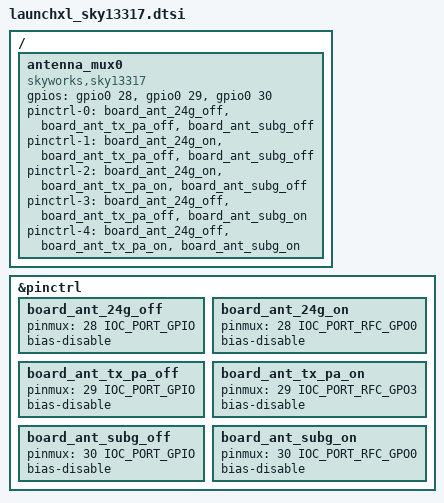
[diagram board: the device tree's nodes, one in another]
/*
 * Copyright (c) 2021 Florin Stancu
 *
 * SPDX-License-Identifier: Apache-2.0
 */

/ {
	/**
	 * The CC1352P LAUNCHXL has an on-board antenna switch (SKY13317-373LF) used to select the
	 * appropriate RF signal port based on the currently-used PHY.
	 *
	 * Truth table:
	 *
	 * Path        DIO28 DIO29 DIO30
	 * =========== ===== ===== =====
	 * Off         0     0     0
	 * Sub-1 GHz   0     0     1     // DIO30 mux to IOC_PORT_RFC_GPO0 for auto
	 * 2.4 GHz     1     0     0     // DIO28 mux to IOC_PORT_RFC_GPO0 for auto
	 * 20 dBm TX   0     1     0     // DIO29 mux to IOC_PORT_RFC_GPO3 for auto
	 */
	antenna_mux0: antenna_mux0 {
		compatible = "skyworks,sky13317";
		status = "okay";
		gpios = <&gpio0 28 GPIO_ACTIVE_HIGH>, <&gpio0 29 GPIO_ACTIVE_HIGH>,
			<&gpio0 30 GPIO_ACTIVE_HIGH>;
		pinctrl-0 = <&board_ant_24g_off &board_ant_tx_pa_off &board_ant_subg_off>;
		pinctrl-1 = <&board_ant_24g_on &board_ant_tx_pa_off &board_ant_subg_off>;
		pinctrl-2 = <&board_ant_24g_on &board_ant_tx_pa_on &board_ant_subg_off>;
		pinctrl-3 = <&board_ant_24g_off &board_ant_tx_pa_off &board_ant_subg_on>;
		pinctrl-4 = <&board_ant_24g_off &board_ant_tx_pa_on &board_ant_subg_on>;
		pinctrl-names = "default", "ant_24g", "ant_24g_pa", "ant_subg", "ant_subg_pa";
	};
};

&pinctrl {
	/* On-board antenna pinmux states */
	board_ant_24g_off: board_ant_24g_off {
		pinmux = <28 IOC_PORT_GPIO>;
		bias-disable;
	};

	board_ant_24g_on: board_ant_24g_on {
		pinmux = <28 IOC_PORT_RFC_GPO0>;
		bias-disable;
	};

	board_ant_tx_pa_off: board_ant_tx_pa_off {
		pinmux = <29 IOC_PORT_GPIO>;
		bias-disable;
	};

	board_ant_tx_pa_on: board_ant_tx_pa_on {
		pinmux = <29 IOC_PORT_RFC_GPO3>;
		bias-disable;
	};

	board_ant_subg_off: board_ant_subg_off {
		pinmux = <30 IOC_PORT_GPIO>;
		bias-disable;
	};

	board_ant_subg_on: board_ant_subg_on {
		pinmux = <30 IOC_PORT_RFC_GPO0>;
		bias-disable;
	};
};
